# STM32U535 register map
File version: 1.0
CPU: CM33 r0p1, little endian, MPU, FPU, 4 interrupt priority bits
Registers are 32-bit, read-write, reset 0x0 unless marked. A register's access mark holds for its fields unless they carry their own. Offsets are from the block's base; [hi:lo] are bit positions; {n}, {i} and the like mark numbered series; 'fields as' and 'values as' point back to an identical list; <NAME> marks a mode.

## RCC (part 2 of 3) — Reset and clock control
Base 0x46020C00
Same registers: SEC_RCC 0x56020C00
0x48 PLL3FRACR — RCC PLL3 fractional divider register
  [15:3] PLL3FRACN range 0..511 — Fractional part of the multiplication factor for PLL3 VCO This bitfield is set and reset by software to control the fractional part of the VCO multiplication factor. It can be written at any time, allowing dynamic fine-tuning of the PLL3 VCO. VCO output frequency = F<sub>ref3_ck</sub> x (PLL3N + (PLL3FRACN / 2<sup>13</sup>)), with: PLL3N must be between 4 and 512. PLL3FRACN can be between 0 and 2<sup>13 </sup>- 1. The input frequency F<sub>ref3_ck</sub> must be between 4 and 16 MHz. In order to change the FRACN value on-the-fly even if the PLL is enabled, the application must proceed as follows: Set the bit PLL3FRACEN to 0. Write the new fractional value into PLL3FRACN. Set the bit PLL3FRACEN to 1.
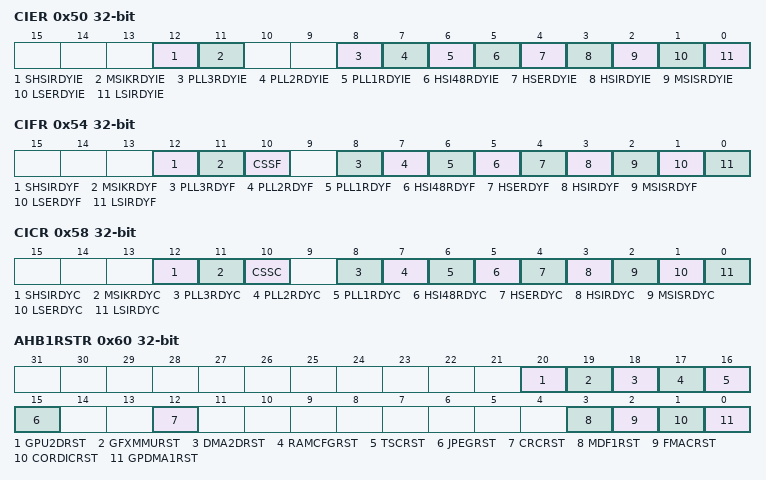
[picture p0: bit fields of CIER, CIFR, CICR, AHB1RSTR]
0x50 CIER — RCC clock interrupt enable register
  [all] fields
    0=Disabled (Interrupt disabled); 1=Enabled (Interrupt enabled)
  [12] SHSIRDYIE — SHSI ready interrupt enable This bit is set and cleared by software to enable/disable interrupt caused by the SHSI oscillator stabilization.
  [11] MSIKRDYIE — MSIK ready interrupt enable This bit is set and cleared by software to enable/disable interrupt caused by the MSIK oscillator stabilization.
  [8] PLL3RDYIE — PLL3 ready interrupt enable This bit is set and cleared by software to enable/disable interrupt caused by PLL3 lock.
  [7] PLL2RDYIE — PLL2 ready interrupt enable This bit is set and cleared by software to enable/disable interrupt caused by PLL2 lock.
  [6] PLL1RDYIE — PLL ready interrupt enable This bit is set and cleared by software to enable/disable interrupt caused by PLL1 lock.
  [5] HSI48RDYIE — HSI48 ready interrupt enable This bit is set and cleared by software to enable/disable interrupt caused by the HSI48 oscillator stabilization.
  [4] HSERDYIE — HSE ready interrupt enable This bit is set and cleared by software to enable/disable interrupt caused by the HSE oscillator stabilization.
  [3] HSIRDYIE — HSI16 ready interrupt enable This bit is set and cleared by software to enable/disable interrupt caused by the HSI16 oscillator stabilization.
  [2] MSISRDYIE — MSIS ready interrupt enable This bit is set and cleared by software to enable/disable interrupt caused by the MSIS oscillator stabilization.
  [1] LSERDYIE — LSE ready interrupt enable This bit is set and cleared by software to enable/disable interrupt caused by the LSE oscillator stabilization.
  [0] LSIRDYIE — LSI ready interrupt enable This bit is set and cleared by software to enable/disable interrupt caused by the LSI oscillator stabilization.
0x54 CIFR ro — RCC clock interrupt flag register
  [12] SHSIRDYF — SHSI ready interrupt flag This bit is set by hardware when the SHSI clock becomes stable and SHSIRDYIE is set. It is cleared by software by setting the SHSIRDYC bit.
    0=NotInterrupted (No clock ready interrupt); 1=Interrupted (Clock ready interrupt)
  [11] MSIKRDYF — MSIK ready interrupt flag This bit is set by hardware when the MSIK clock becomes stable and MSIKRDYIE is set. It is cleared by software by setting the MSIKRDYC bit.
    values as SHSIRDYF
  [10] CSSF — Clock security system interrupt flag This bit is set by hardware when a failure is detected in the HSE oscillator. It is cleared by software by setting the CSSC bit.
  [8] PLL3RDYF — PLL3 ready interrupt flag This bit is set by hardware when the PLL3 locks and PLL3RDYIE is set. It is cleared by software by setting the PLL3RDYC bit.
    values as SHSIRDYF
  [7] PLL2RDYF — PLL2 ready interrupt flag This bit is set by hardware when the PLL2 locks and PLL2RDYIE is set. It is cleared by software by setting the PLL2RDYC bit.
    values as SHSIRDYF
  [6] PLL1RDYF — PLL1 ready interrupt flag This bit is set by hardware when the PLL1 locks and PLL1RDYIE is set. It is cleared by software by setting the PLL1RDYC bit.
    values as SHSIRDYF
  [5] HSI48RDYF — HSI48 ready interrupt flag This bit is set by hardware when the HSI48 clock becomes stable and HSI48RDYIE is set. it�is cleared by software by setting the HSI48RDYC bit.
    values as SHSIRDYF
  [4] HSERDYF — HSE ready interrupt flag This bit is set by hardware when the HSE clock becomes stable and HSERDYIE is set. It is cleared by software by setting the HSERDYC bit.
    values as SHSIRDYF
  [3] HSIRDYF — HSI16 ready interrupt flag This bit is set by hardware when the HSI16 clock becomes stable and HSIRDYIE = 1 in�response to setting the HSION (see RCC_CR). When HSION = 0 but the HSI16 oscillator is enabled by the peripheral through a clock request, this bit is not set and no interrupt is generated. This bit is cleared by software by setting the HSIRDYC bit.
    values as SHSIRDYF
  [2] MSISRDYF — MSIS ready interrupt flag This bit is set by hardware when the MSIS clock becomes stable and MSISRDYIE is set. It�is cleared by software by setting the MSISRDYC bit.
    values as SHSIRDYF
  [1] LSERDYF — LSE ready interrupt flag This bit is set by hardware when the LSE clock becomes stable and LSERDYIE is set. It is cleared by software by setting the LSERDYC bit.
    values as SHSIRDYF
  [0] LSIRDYF — LSI ready interrupt flag This bit is set by hardware when the LSI clock becomes stable and LSIRDYIE is set. It is cleared by software by�setting the LSIRDYC bit.
    values as SHSIRDYF
0x58 CICR wo — RCC clock interrupt clear register
  [12] SHSIRDYC — SHSI oscillator ready interrupt clear Writing this bit to 1 clears the SHSIRDYF flag. Writing 0 has no effect.
    1=Clear flag
  [11] MSIKRDYC — MSIK oscillator ready interrupt clear Writing this bit to 1 clears the MSIKRDYF flag. Writing 0 has no effect.
    1=Clear flag
  [10] CSSC — Clock security system interrupt clear Writing this bit to 1 clears the CSSF flag. Writing 0 has no effect.
  [8] PLL3RDYC — PLL3 ready interrupt clear Writing this bit to 1 clears the PLL3RDYF flag. Writing 0 has no effect.
    1=Clear flag
  [7] PLL2RDYC — PLL2 ready interrupt clear Writing this bit to 1 clears the PLL2RDYF flag. Writing 0 has no effect.
    1=Clear flag
  [6] PLL1RDYC — PLL1 ready interrupt clear Writing this bit to 1 clears the PLL1RDYF flag. Writing 0 has no effect.
    1=Clear flag
  [5] HSI48RDYC — HSI48 ready interrupt clear Writing this bit to 1 clears the HSI48RDYF flag. Writing 0 has no effect.
    1=Clear flag
  [4] HSERDYC — HSE ready interrupt clear Writing this bit to 1 clears the HSERDYF flag. Writing 0 has no effect.
    1=Clear flag
  [3] HSIRDYC — HSI16 ready interrupt clear Writing this bit to 1 clears the HSIRDYF flag. Writing 0 has no effect.
    1=Clear flag
  [2] MSISRDYC — MSIS ready interrupt clear Writing this bit to 1 clears the MSISRDYF flag. Writing 0 has no effect.
    1=Clear flag
  [1] LSERDYC — LSE ready interrupt clear Writing this bit to 1 clears the LSERDYF flag. Writing 0 has no effect.
    1=Clear flag
  [0] LSIRDYC — LSI ready interrupt clear Writing this bit to 1 clears the LSIRDYF flag. Writing 0 has no effect.
    1=Clear flag
0x60 AHB1RSTR — RCC AHB1 peripheral reset register
  [all] fields
    0=NoEffect; 1=Reset peripheral
  [20] GPU2DRST — GPU2D reset This bit is set and cleared by software. Note: This bit is only available on some devices in the STM32U5 Series. Refer to the device datasheet for availability of its associated peripheral. If not present, consider this bit as reserved and keep it at reset value.
  [19] GFXMMURST — GFXMMU reset This bit is set and cleared by software. Note: This bit is only available on some devices in the STM32U5 Series. Refer to the device datasheet for availability of its associated peripheral. If not present, consider this bit as reserved and keep it at reset value.
  [18] DMA2DRST — DMA2D reset This bit is set and cleared by software. Note: This bit is only available on some devices in the STM32U5 Series. Refer to the device datasheet for availability of its associated peripheral. If not present, consider this bit as reserved and keep it at reset value.
  [17] RAMCFGRST — RAMCFG reset This bit is set and cleared by software.
  [16] TSCRST — TSC reset This bit is set and cleared by software.
  [15] JPEGRST — JPEG reset This bit is set and cleared by software. Note: This bit is only available on some devices in the STM32U5 Series. Refer to the device datasheet for availability of its associated peripheral. If not present, consider this bit as reserved and keep it at reset value.
  [12] CRCRST — CRC reset This bit is set and cleared by software.
  [3] MDF1RST — MDF1 reset This bit is set and cleared by software.
  [2] FMACRST — FMAC reset This bit is set and cleared by software.
  [1] CORDICRST — CORDIC reset This bit is set and cleared by software.
  [0] GPDMA1RST — GPDMA1 reset This bit is set and cleared by software.
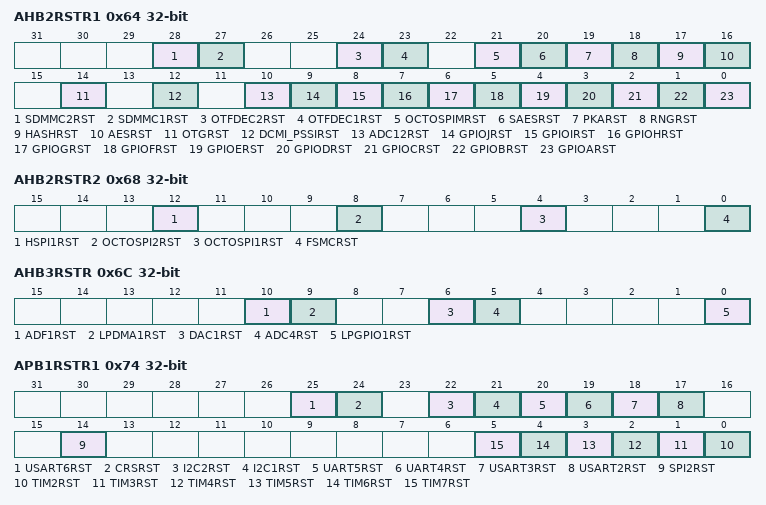
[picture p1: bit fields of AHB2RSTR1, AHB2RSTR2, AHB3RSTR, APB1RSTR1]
0x64 AHB2RSTR1 — RCC AHB2 peripheral reset register 1
  [all] fields
    0=NoEffect; 1=Reset peripheral
  [28] SDMMC2RST — SDMMC2 reset This bit is set and cleared by software. Note: This bit is only available on some devices in the STM32U5 Series. Refer to the device datasheet for availability of its associated peripheral. If not present, consider this bit as reserved and keep it at reset value.
  [27] SDMMC1RST — SDMMC1 reset This bit is set and cleared by software.
  [24] OTFDEC2RST — OTFDEC2 reset This bit is set and cleared by software. Note: This bit is only available on some devices in the STM32U5 Series. Refer to the device datasheet for availability of its associated peripheral. If not present, consider this bit as reserved and keep it at reset value.
  [23] OTFDEC1RST — OTFDEC1 reset This bit is set and cleared by software. Note: This bit is only available on some devices in the STM32U5 Series. Refer to the device datasheet for availability of its associated peripheral. If not present, consider this bit as reserved and keep it at reset value.
  [21] OCTOSPIMRST — OCTOSPIM reset This bit is set and cleared by software. Note: This bit is only available on some devices in the STM32U5 Series. Refer to the device datasheet for availability of its associated peripheral. If not present, consider this bit as reserved and keep it at reset value.
  [20] SAESRST — SAES hardware accelerator reset This bit is set and cleared by software. Note: This bit is only available on some devices in the STM32U5 Series. Refer to the device datasheet for availability of its associated peripheral. If not present, consider this bit as reserved and keep it at reset value.
  [19] PKARST — PKA reset This bit is set and cleared by software. Note: This bit is only available on some devices in the STM32U5 Series. Refer to the device datasheet for availability of its associated peripheral. If not present, consider this bit as reserved and keep it at reset value.
  [18] RNGRST — RNG reset This bit is set and cleared by software.
  [17] HASHRST — HASH reset This bit is set and cleared by software.
  [16] AESRST — AES hardware accelerator reset This bit is set and cleared by software. Note: This bit is only available on some devices in the STM32U5 Series. Refer to the device datasheet for availability of its associated peripheral. If not present, consider this bit as reserved and keep it at reset value.
  [14] OTGRST — OTG_FS or OTG_HS reset This bit is set and cleared by software. Note: This bit is only available on some devices in the STM32U5 Series. Refer to the device datasheet for availability of its associated peripheral. If not present, consider this bit as reserved and keep it at reset value.
  [12] DCMI_PSSIRST — DCMI and PSSI reset This bit is set and cleared by software.
  [10] ADC12RST — ADC1 and ADC2 reset This bit is set and cleared by software. Note: This bit impacts ADC1 in STM32U535/545/575/585, and ADC1/ADC2 in�STM32U59x/5Ax/5Fx/5Gx.
  [9] GPIOJRST — I/O port J reset This bit is set and cleared by software. Note: This bit is only available on some devices in the STM32U5 Series. Refer to the device datasheet for availability of its associated peripheral. If not present, consider this bit as reserved and keep it at reset value.
  [8] GPIOIRST — I/O port I reset This bit is set and cleared by software. Note: This bit is only available on some devices in the STM32U5 Series. Refer to the device datasheet for availability of its associated peripheral. If not present, consider this bit as reserved and keep it at reset value.
  [7] GPIOHRST — I/O port H reset This bit is set and cleared by software.
  [6] GPIOGRST — I/O port G reset This bit is set and cleared by software.
  [5] GPIOFRST — I/O port F reset This bit is set and cleared by software. This bit is only available on some devices in the STM32U5 Series. Refer to the device datasheet for availability of its associated peripheral. Note: If not present, consider this bit as reserved and keep it at reset value.
  [4] GPIOERST — I/O port E reset This bit is set and cleared by software.
  [3] GPIODRST — I/O port D reset This bit is set and cleared by software.
  [2] GPIOCRST — I/O port C reset This bit is set and cleared by software.
  [1] GPIOBRST — I/O port B reset This bit is set and cleared by software.
  [0] GPIOARST — I/O port A reset This bit is set and cleared by software.
0x68 AHB2RSTR2 — RCC AHB2 peripheral reset register 2
  [all] fields
    0=NoEffect; 1=Reset peripheral
  [12] HSPI1RST — HSPI1 reset This bit is set and cleared by software. Note: This bit is only available on some devices in the STM32U5 Series. Refer to the device datasheet for availability of its associated peripheral. If not present, consider this bit as reserved and keep it at reset value.
  [8] OCTOSPI2RST — OCTOSPI2 reset This bit is set and cleared by software. Note: This bit is only available on some devices in the STM32U5 Series. Refer to the device datasheet for availability of its associated peripheral. If not present, consider this bit as reserved and keep it at reset value.
  [4] OCTOSPI1RST — OCTOSPI1 reset This bit is set and cleared by software.
  [0] FSMCRST — Flexible memory controller reset This bit is set and cleared by software. Note: This bit is only available on some devices in the STM32U5 Series. Refer to the device datasheet for availability of its associated peripheral. If not present, consider this bit as reserved and keep it at reset value.
0x6C AHB3RSTR — RCC AHB3 peripheral reset register
  [all] fields
    0=NoEffect; 1=Reset peripheral
  [10] ADF1RST — ADF1 reset This bit is set and cleared by software.
  [9] LPDMA1RST — LPDMA1 reset This bit is set and cleared by software.
  [6] DAC1RST — DAC1 reset This bit is set and cleared by software.
  [5] ADC4RST — ADC4 reset This bit is set and cleared by software.
  [0] LPGPIO1RST — LPGPIO1 reset This bit is set and cleared by software.
0x74 APB1RSTR1 — RCC APB1 peripheral reset register 1
  [all] fields
    0=NoEffect; 1=Reset peripheral
  [25] USART6RST — USART6 reset This bit is set and cleared by software. Note: This bit is only available on some devices in the STM32U5 Series. Refer to the device datasheet for availability of its associated peripheral. If not present, consider this bit as reserved and keep it at reset value.
  [24] CRSRST — CRS reset This bit is set and cleared by software.
  [22] I2C2RST — I2C2 reset This bit is set and cleared by software.
  [21] I2C1RST — I2C1 reset This bit is set and cleared by software.
  [20] UART5RST — UART5 reset This bit is set and cleared by software.
  [19] UART4RST — UART4 reset This bit is set and cleared by software.
  [18] USART3RST — USART3 reset This bit is set and cleared by software.
  [17] USART2RST — USART2 reset This bit is set and cleared by software. Note: This bit is only available on some devices in the STM32U5 Series.Refer to the device datasheet for availability of its associated peripheral. If not present, consider this bit as reserved and keep it at reset value.
  [14] SPI2RST — SPI2 reset This bit is set and cleared by software.
  [n-2] TIM{n}RST (n=2..7) — TIM{n} reset This bit is set and cleared by software.
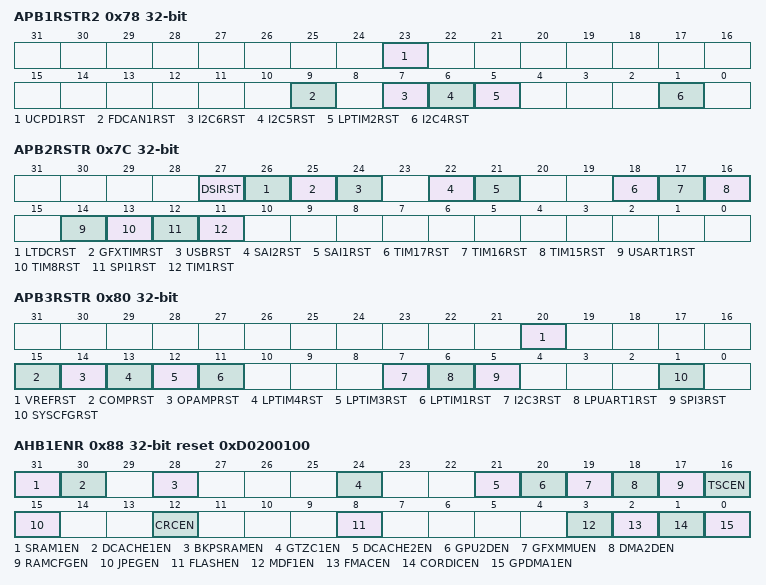
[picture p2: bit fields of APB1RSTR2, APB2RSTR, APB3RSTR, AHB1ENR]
0x78 APB1RSTR2 — RCC APB1 peripheral reset register 2
  [all] fields
    0=NoEffect; 1=Reset peripheral
  [23] UCPD1RST — UCPD1 reset This bit is set and cleared by software. Note: This bit is only available on some devices in the STM32U5 Series. Refer to the device datasheet for availability of its associated peripheral. If not present, consider this bit as reserved and keep it at reset value.
  [9] FDCAN1RST — FDCAN1 reset This bit is set and cleared by software.
  [7] I2C6RST — I2C6 reset This bit is set and cleared by software Note: This bit is only available on some devices in the STM32U5 Series. Refer to the device datasheet for availability of its associated peripheral. If not present, consider this bit as reserved and keep it at reset value.
  [6] I2C5RST — I2C5 reset This bit is set and cleared by software Note: This bit is only available on some devices in the STM32U5 Series. Refer to the device datasheet for availability of its associated peripheral. If not present, consider this bit as reserved and keep it at reset value.
  [5] LPTIM2RST — LPTIM2 reset This bit is set and cleared by software.
  [1] I2C4RST — I2C4 reset This bit is set and cleared by software
0x7C APB2RSTR — RCC APB2 peripheral reset register
  [all] fields
    0=NoEffect; 1=Reset peripheral
  [27] DSIRST — DSI reset This bit is set and cleared by software. Note: This bit is only available on some devices in the STM32U5 Series. Refer to the device datasheet for availability of its associated peripheral. If not present, consider this bit as reserved and keep it at reset value.
  [26] LTDCRST — LTDC reset This bit is set and cleared by software. Note: This bit is only available on some devices in the STM32U5 Series. Refer to the device datasheet for availability of its associated peripheral. If not present, consider this bit as reserved and keep it at reset value.
  [25] GFXTIMRST — GFXTIM reset This bit is set and cleared by software. Note: .This bit is only available on some devices in the STM32U5 Series. Refer to the device datasheet for availability of its associated peripheral. If not present, consider this bit as reserved and keep it at reset value.
  [24] USBRST — USB reset This bit is set and cleared by software. Note: This bit is only available on some devices in the STM32U5 Series. Refer to the device datasheet for availability of its associated peripheral. If not present, consider this bit as reserved and keep it at reset value.
  [22] SAI2RST — SAI2 reset This bit is set and cleared by software. Note: This bit is only available on some devices in the STM32U5 Series. Refer to the device datasheet for availability of its associated peripheral. If not present, consider this bit as reserved and keep it at reset value.
  [21] SAI1RST — SAI1 reset This bit is set and cleared by software.
  [18] TIM17RST — TIM17 reset This bit is set and cleared by software.
  [17] TIM16RST — TIM16 reset This bit is set and cleared by software.
  [16] TIM15RST — TIM15 reset This bit is set and cleared by software.
  [14] USART1RST — USART1 reset This bit is set and cleared by software.
  [13] TIM8RST — TIM8 reset This bit is set and cleared by software.
  [12] SPI1RST — SPI1 reset This bit is set and cleared by software.
  [11] TIM1RST — TIM1 reset This bit is set and cleared by software.
0x80 APB3RSTR — RCC APB3 peripheral reset register
  [all] fields
    0=NoEffect; 1=Reset peripheral
  [20] VREFRST — VREFBUF reset This bit is set and cleared by software.
  [15] COMPRST — COMP reset This bit is set and cleared by software.
  [14] OPAMPRST — OPAMP reset This bit is set and cleared by software.
  [13] LPTIM4RST — LPTIM4 reset This bit is set and cleared by software.
  [12] LPTIM3RST — LPTIM3 reset This bit is set and cleared by software.
  [11] LPTIM1RST — LPTIM1 reset This bit is set and cleared by software.
  [7] I2C3RST — I2C3 reset This bit is set and cleared by software.
  [6] LPUART1RST — LPUART1 reset This bit is set and cleared by software.
  [5] SPI3RST — SPI3 reset This bit is set and cleared by software.
  [1] SYSCFGRST — SYSCFG reset This bit is set and cleared by software.
0x88 AHB1ENR reset 0xD0200100 — RCC AHB1 peripheral clock enable register
  [all] fields
    0=Disabled (Peripheral clock disabled); 1=Enabled (Peripheral clock enabled)
  [31] SRAM1EN — SRAM1 clock enable This bit is set and reset by software.
  [30] DCACHE1EN — DCACHE1 clock enable This bit is set and reset by software. Note: DCACHE1 clock must be enabled when external memories are accessed through OCTOSPI1, OCTOSPI2, HSPI1 or FSMC, even if the DCACHE1 is bypassed.
  [28] BKPSRAMEN — BKPSRAM clock enable This bit is set and reset by software.
  [24] GTZC1EN — GTZC1 clock enable This bit is set and reset by software.
  [21] DCACHE2EN — DCACHE2 clock enable This bit is set and reset by software. Note: DCACHE2 clock must be enabled to access memories, even if the DCACHE2 is bypassed. Note: This bit is only available on some devices in the STM32U5 Series. Refer to the device datasheet for availability of its associated peripheral. If not present, consider this bit as reserved and keep it at reset value.
  [20] GPU2DEN — GPU2D clock enable This bit is set and cleared by software. Note: This bit is only available on some devices in the STM32U5 Series. Refer to the device datasheet for availability of its associated peripheral. If not present, consider this bit as reserved and keep it at reset value.
  [19] GFXMMUEN — GFXMMU clock enable This bit is set and cleared by software. Note: This bit is only available on some devices in the STM32U5 Series. Refer to the device datasheet for availability of its associated peripheral. If not present, consider this bit as reserved and keep it at reset value.
  [18] DMA2DEN — DMA2D clock enable This bit is set and cleared by software. Note: This bit is only available on some devices in the STM32U5 Series. Refer to the device datasheet for availability of its associated peripheral. If not present, consider this bit as reserved and keep it at reset value.
  [17] RAMCFGEN — RAMCFG clock enable This bit is set and cleared by software.
  [16] TSCEN — Touch sensing controller clock enable This bit is set and cleared by software.
  [15] JPEGEN — JPEG clock enable This bit is set and cleared by software. Note: This bit is only available on some devices in the STM32U5 Series. Refer to the device datasheet for availability of its associated peripheral. If not present, consider this bit as reserved and keep it at reset value.
  [12] CRCEN — CRC clock enable This bit is set and cleared by software.
  [8] FLASHEN — FLASH clock enable This bit is set and cleared by software. This bit can be disabled only when the flash memory is in power-down mode.
  [3] MDF1EN — MDF1 clock enable This bit is set and reset by software.
  [2] FMACEN — FMAC clock enable This bit is set and reset by software.
  [1] CORDICEN — CORDIC clock enable This bit is set and cleared by software.
  [0] GPDMA1EN — GPDMA1 clock enable This bit is set and cleared by software.
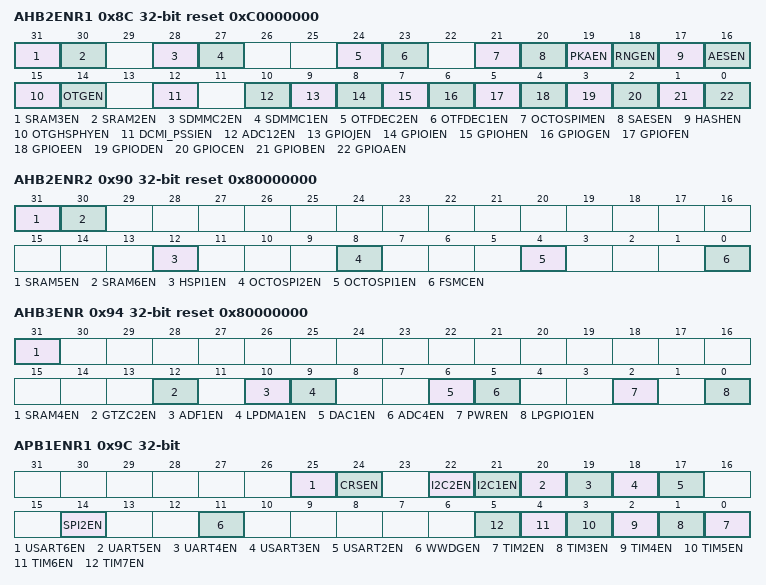
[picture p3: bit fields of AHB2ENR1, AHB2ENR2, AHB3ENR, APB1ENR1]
0x8C AHB2ENR1 reset 0xC0000000 — RCC AHB2 peripheral clock enable register 1
  [all] fields
    values as the fields of AHB1ENR
  [31] SRAM3EN — SRAM3 clock enable This bit is set and reset by software. Note: This bit is only available on some devices in the STM32U5 Series. Refer to the device datasheet for availability of its associated peripheral. If not present, consider this bit as reserved and keep it at reset value.
  [30] SRAM2EN — SRAM2 clock enable This bit is set and reset by software.
  [28] SDMMC2EN — SDMMC2 clock enable This bit is set and cleared by software. Note: This bit is only available on some devices in the STM32U5 Series. Refer to the device datasheet for availability of its associated peripheral. If not present, consider this bit as reserved and keep it at reset value.
  [27] SDMMC1EN — SDMMC1 clock enable This bit is set and cleared by software.
  [24] OTFDEC2EN — OTFDEC2 clock enable This bit is set and cleared by software. Note: This bit is only available on some devices in the STM32U5 Series. Refer to the device datasheet for availability of its associated peripheral. If not present, consider this bit as reserved and keep it at reset value.
  [23] OTFDEC1EN — OTFDEC1 clock enable This bit is set and cleared by software. Note: This bit is only available on some devices in the STM32U5 Series. Refer to the device datasheet for availability of its associated peripheral. If not present, consider this bit as reserved and keep it at reset value.
  [21] OCTOSPIMEN — OCTOSPIM clock enable This bit is set and cleared by software. Note: This bit is only available on some devices in the STM32U5 Series. Refer to the device datasheet for availability of its associated peripheral. If not present, consider this bit as reserved and keep it at reset value.
  [20] SAESEN — SAES clock enable This bit is set and cleared by software. Note: This bit is only available on some devices in the STM32U5 Series. Refer to the device datasheet for availability of its associated peripheral. If not present, consider this bit as reserved and keep it at reset value.
  [19] PKAEN — PKA clock enable This bit is set and cleared by software. Note: This bit is only available on some devices in the STM32U5 Series. Refer to the device datasheet for availability of its associated peripheral. If not present, consider this bit as reserved and keep it at reset value.
  [18] RNGEN — RNG clock enable This bit is set and cleared by software.
  [17] HASHEN — HASH clock enable This bit is set and cleared by software
  [16] AESEN — AES clock enable This bit is set and cleared by software. Note: This bit is only available on some devices in the STM32U5 Series. Refer to the device datasheet for availability of its associated peripheral. If not present, consider this bit as reserved and keep it at reset value.
  [15] OTGHSPHYEN — OTG_HS PHY clock enable This bit is set and cleared by software. Note: This bit is only available on some devices in the STM32U5 Series. Refer to the device datasheet for availability of its associated peripheral. If not present, consider this bit as reserved and keep it at reset value.
  [14] OTGEN — OTG_FS or OTG_HS clock enable This bit is set and cleared by software. Note: This bit is only available on some devices in the STM32U5 Series. Refer to the device datasheet for availability of its associated peripheral. If not present, consider this bit as reserved and keep it at reset value.
  [12] DCMI_PSSIEN — DCMI and PSSI clock enable This bit is set and cleared by software.
  [10] ADC12EN — ADC1 and ADC2 clock enable This bit is set and cleared by software. Note: This bit impacts ADC1 in STM32U535/545/575/585, and ADC1/ADC2 in�STM32U59x/5Ax/5Fx/5Gx.
  [9] GPIOJEN — I/O port J clock enable This bit is set and cleared by software. Note: This bit is only available on some devices in the STM32U5 Series. Refer to the device datasheet for availability of its associated peripheral. If not present, consider this bit as reserved and keep it at reset value.
  [8] GPIOIEN — I/O port I clock enable This bit is set and cleared by software. Note: This bit is only available on some devices in the STM32U5 Series. Refer to the device datasheet for availability of its associated peripheral. If not present, consider this bit as reserved and keep it at reset value.
  [7] GPIOHEN — I/O port H clock enable This bit is set and cleared by software.
  [6] GPIOGEN — I/O port G clock enable This bit is set and cleared by software.
  [5] GPIOFEN — I/O port F clock enable This bit is set and cleared by software. Note: This bit is only available on some devices in the STM32U5 Series. Refer to the device datasheet for availability of its associated peripheral. If not present, consider this bit as reserved and keep it at reset value.
  [4] GPIOEEN — I/O port E clock enable This bit is set and cleared by software.
  [3] GPIODEN — I/O port D clock enable This bit is set and cleared by software.
  [2] GPIOCEN — I/O port C clock enable This bit is set and cleared by software.
  [1] GPIOBEN — I/O port B clock enable This bit is set and cleared by software.
  [0] GPIOAEN — I/O port A clock enable This bit is set and cleared by software.
0x90 AHB2ENR2 reset 0x80000000 — RCC AHB2 peripheral clock enable register 2
  [all] fields
    values as the fields of AHB1ENR
  [31] SRAM5EN — SRAM5 clock enable This bit is set and reset by software. Note: This bit is only available on some devices in the STM32U5 Series. Refer to the device datasheet for availability of its associated peripheral. If not present, consider this bit as reserved and keep it at reset value.
  [30] SRAM6EN — SRAM6 clock enable This bit is set and reset by software. Note: This bit is only available on some devices in the STM32U5 Series. Refer to the device datasheet for availability of its associated peripheral. If not present, consider this bit as reserved and keep it at reset value.
  [12] HSPI1EN — HSPI1 clock enable This bit is set and cleared by software. Note: This bit is only available on some devices in the STM32U5 Series. Refer to the device datasheet for availability of its associated peripheral. If not present, consider this bit as reserved and keep it at reset value.
  [8] OCTOSPI2EN — OCTOSPI2 clock enable This bit is set and cleared by software. Note: This bit is only available on some devices in the STM32U5 Series. Refer to the device datasheet for availability of its associated peripheral. If not present, consider this bit as reserved and keep it at reset value.
  [4] OCTOSPI1EN — OCTOSPI1 clock enable This bit is set and cleared by software.
  [0] FSMCEN — FSMC clock enable This bit is set and cleared by software. Note: This bit is only available on some devices in the STM32U5 Series. Refer to the device datasheet for availability of its associated peripheral. If not present, consider this bit as reserved and keep it at reset value.
0x94 AHB3ENR reset 0x80000000 — RCC AHB3 peripheral clock enable register
  [all] fields
    values as the fields of AHB1ENR
  [31] SRAM4EN — SRAM4 clock enable This bit is set and reset by software.
  [12] GTZC2EN — GTZC2 clock enable This bit is set and cleared by software.
  [10] ADF1EN — ADF1 clock enable This bit is set and cleared by software.
  [9] LPDMA1EN — LPDMA1 clock enable This bit is set and cleared by software.
  [6] DAC1EN — DAC1 clock enable This bit is set and cleared by software.
  [5] ADC4EN — ADC4 clock enable This bit is set and cleared by software.
  [2] PWREN — PWR clock enable This bit is set and cleared by software.
  [0] LPGPIO1EN — LPGPIO1 enable This bit is set and cleared by software.
0x9C APB1ENR1 — RCC APB1 peripheral clock enable register 1
  [all] fields
    values as the fields of AHB1ENR
  [25] USART6EN — USART6 clock enable This bit is set and cleared by software. Note: This bit is only available on some devices in the STM32U5 Series. Refer to the device datasheet for availability of its associated peripheral. If not present, consider this bit as reserved and keep it at reset value.
  [24] CRSEN — CRS clock enable This bit is set and cleared by software.
  [22] I2C2EN — I2C2 clock enable This bit is set and cleared by software.
  [21] I2C1EN — I2C1 clock enable This bit is set and cleared by software.
  [20] UART5EN — UART5 clock enable This bit is set and cleared by software.
  [19] UART4EN — UART4 clock enable This bit is set and cleared by software.
  [18] USART3EN — USART3 clock enable This bit is set and cleared by software.
  [17] USART2EN — USART2 clock enable This bit is set and cleared by software. Note: This bit is only available on some devices in the STM32U5 Series. Refer to the device datasheet for availability of its associated peripheral. If not present, consider this bit as reserved and keep it at reset value.
  [14] SPI2EN — SPI2 clock enable This bit is set and cleared by software.
  [11] WWDGEN — WWDG clock enable This bit is set by software to enable the window watchdog clock. It is reset by hardware system reset. This bit can also be set by hardware if the WWDG_SW option bit is reset.
  [n-2] TIM{n}EN (n=2..7) — TIM{n} clock enable This bit is set and cleared by software.
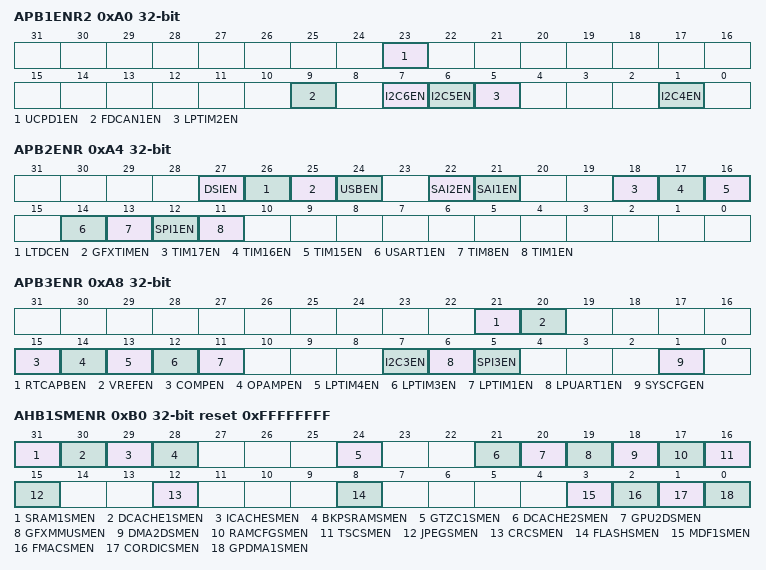
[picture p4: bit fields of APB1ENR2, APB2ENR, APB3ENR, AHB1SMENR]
0xA0 APB1ENR2 — RCC APB1 peripheral clock enable register 2
  [all] fields
    values as the fields of AHB1ENR
  [23] UCPD1EN — UCPD1 clock enable This bit is set and cleared by software. Note: This bit is only available on some devices in the STM32U5 Series. Refer to the device datasheet for availability of its associated peripheral. If not present, consider this bit as reserved and keep it at reset value.
  [9] FDCAN1EN — FDCAN1 clock enable This bit is set and cleared by software.
  [7] I2C6EN — I2C6 clock enable This bit is set and cleared by software. Note: This bit is only available on some devices in the STM32U5 Series. Refer to the device datasheet for availability of its associated peripheral. If not present, consider this bit as reserved and keep it at reset value.
  [6] I2C5EN — I2C5 clock enable This bit is set and cleared by software. Note: This bit is only available on some devices in the STM32U5 Series. Refer to the device datasheet for availability of its associated peripheral. If not present, consider this bit as reserved and keep it at reset value.
  [5] LPTIM2EN — LPTIM2 clock enable This bit is set and cleared by software.
  [1] I2C4EN — I2C4 clock enable This bit is set and cleared by software
0xA4 APB2ENR — RCC APB2 peripheral clock enable register
  [all] fields
    values as the fields of AHB1ENR
  [27] DSIEN — DSI clock enable This bit is set and cleared by software. Note: This bit is only available on some devices in the STM32U5 Series. Refer to the device datasheet for availability of its associated peripheral. If not present, consider this bit as reserved and keep it at reset value.
  [26] LTDCEN — LTDC clock enable This bit is set and cleared by software. Note: This bit is only available on some devices in the STM32U5 Series. Refer to the device datasheet for availability of its associated peripheral. If not present, consider this bit as reserved and keep it at reset value.
  [25] GFXTIMEN — GFXTIM clock enable This bit is set and cleared by software. Note: This bit is only available on some devices in the STM32U5 Series. Refer to the device datasheet for availability of its associated peripheral. If not present, consider this bit as reserved and keep it at reset value.
  [24] USBEN — USB clock enable This bit is set and cleared by software. Note: This bit is only available on some devices in the STM32U5 Series. Refer to the device datasheet for availability of its associated peripheral. If not present, consider this bit as reserved and keep it at reset value.
  [22] SAI2EN — SAI2 clock enable This bit is set and cleared by software. Note: This bit is only available on some devices in the STM32U5 Series. Refer to the device datasheet for availability of its associated peripheral. If not present, consider this bit as reserved and keep it at reset value.
  [21] SAI1EN — SAI1 clock enable This bit is set and cleared by software.
  [18] TIM17EN — TIM17 clock enable This bit is set and cleared by software.
  [17] TIM16EN — TIM16 clock enable This bit is set and cleared by software.
  [16] TIM15EN — TIM15 clock enable This bit is set and cleared by software.
  [14] USART1EN — USART1clock enable This bit is set and cleared by software.
  [13] TIM8EN — TIM8 clock enable This bit is set and cleared by software.
  [12] SPI1EN — SPI1 clock enable This bit is set and cleared by software.
  [11] TIM1EN — TIM1 clock enable This bit is set and cleared by software.
0xA8 APB3ENR — RCC APB3 peripheral clock enable register
  [all] fields
    values as the fields of AHB1ENR
  [21] RTCAPBEN — RTC and TAMP APB clock enable This bit is set and cleared by software.
  [20] VREFEN — VREFBUF clock enable This bit is set and cleared by software.
  [15] COMPEN — COMP clock enable This bit is set and cleared by software.
  [14] OPAMPEN — OPAMP clock enable This bit is set and cleared by software.
  [13] LPTIM4EN — LPTIM4 clock enable This bit is set and cleared by software.
  [12] LPTIM3EN — LPTIM3 clock enable This bit is set and cleared by software.
  [11] LPTIM1EN — LPTIM1 clock enable This bit is set and cleared by software.
  [7] I2C3EN — I2C3 clock enable This bit is set and cleared by software.
  [6] LPUART1EN — LPUART1 clock enable This bit is set and cleared by software.
  [5] SPI3EN — SPI3 clock enable This bit is set and cleared by software.
  [1] SYSCFGEN — SYSCFG clock enable This bit is set and cleared by software.
0xB0 AHB1SMENR reset 0xFFFFFFFF — RCC AHB1 peripheral clock enable in Sleep and Stop modes register
  [all] fields
    0=Disabled (Peripheral clocks disabled by the clock gating during Sleep and Stop modes); 1=Enabled (Peripheral clocks enabled by the clock gating during Sleep and Stop modes)
  [31] SRAM1SMEN — SRAM1 clock enable during Sleep and Stop modes This bit is set and cleared by software.
  [30] DCACHE1SMEN — DCACHE1 clock enable during Sleep and Stop modes This bit is set and cleared by software.
  [29] ICACHESMEN — ICACHE clock enable during Sleep and Stop modes This bit is set and cleared by software.
  [28] BKPSRAMSMEN — BKPSRAM clock enable during Sleep and Stop modes This bit is set and cleared by software
  [24] GTZC1SMEN — GTZC1 clock enable during Sleep and Stop modes This bit is set and cleared by software.
  [21] DCACHE2SMEN — DCACHE2 clock enable during Sleep and Stop modes This bit is set and cleared by software. Note: This bit is only available on some devices in the STM32U5 Series. Refer to the device datasheet for availability of its associated peripheral. If not present, consider this bit as reserved and keep it at reset value.
  [20] GPU2DSMEN — GPU2D clock enable during Sleep and Stop modes This bit is set and cleared by software. Note: This bit is only available on some devices in the STM32U5 Series. Refer to the device datasheet for availability of its associated peripheral. If not present, consider this bit as reserved and keep it at reset value.
  [19] GFXMMUSMEN — GFXMMU clock enable during Sleep and Stop modes This bit is set and cleared by software. Note: This bit is only available on some devices in the STM32U5 Series. Refer to the device datasheet for availability of its associated peripheral. If not present, consider this bit as reserved and keep it at reset value.
  [18] DMA2DSMEN — DMA2D clock enable during Sleep and Stop modes This bit is set and cleared by software. Note: This bit is only available on some devices in the STM32U5 Series. Refer to the device datasheet for availability of its associated peripheral. If not present, consider this bit as reserved and keep it at reset value.
  [17] RAMCFGSMEN — RAMCFG clock enable during Sleep and Stop modes This bit is set and cleared by software.
  [16] TSCSMEN — TSC clocks enable during Sleep and Stop modes This bit is set and cleared by software.
  [15] JPEGSMEN — JPEG clocks enable during Sleep and Stop modes This bit is set and cleared by software. Note: This bit is only available on some devices in the STM32U5 Series. Refer to the device datasheet for availability of its associated peripheral. If not present, consider this bit as reserved and keep it at reset value.
  [12] CRCSMEN — CRC clocks enable during Sleep and Stop modes This bit is set and cleared by software.
  [8] FLASHSMEN — FLASH clocks enable during Sleep and Stop modes This bit is set and cleared by software.
  [3] MDF1SMEN — MDF1 clocks enable during Sleep and Stop modes. This bit is set and cleared by software. Note: This bit must be set to allow the peripheral to wake up from Stop modes.
  [2] FMACSMEN — FMAC clocks enable during Sleep and Stop modes. This bit is set and cleared by software.
  [1] CORDICSMEN — CORDIC clocks enable during Sleep and Stop modes This bit is set and cleared by software during Sleep mode.
  [0] GPDMA1SMEN — GPDMA1 clocks enable during Sleep and Stop modes This bit is set and cleared by software. Note: This bit must be set to allow the peripheral to wake up from Stop modes.
